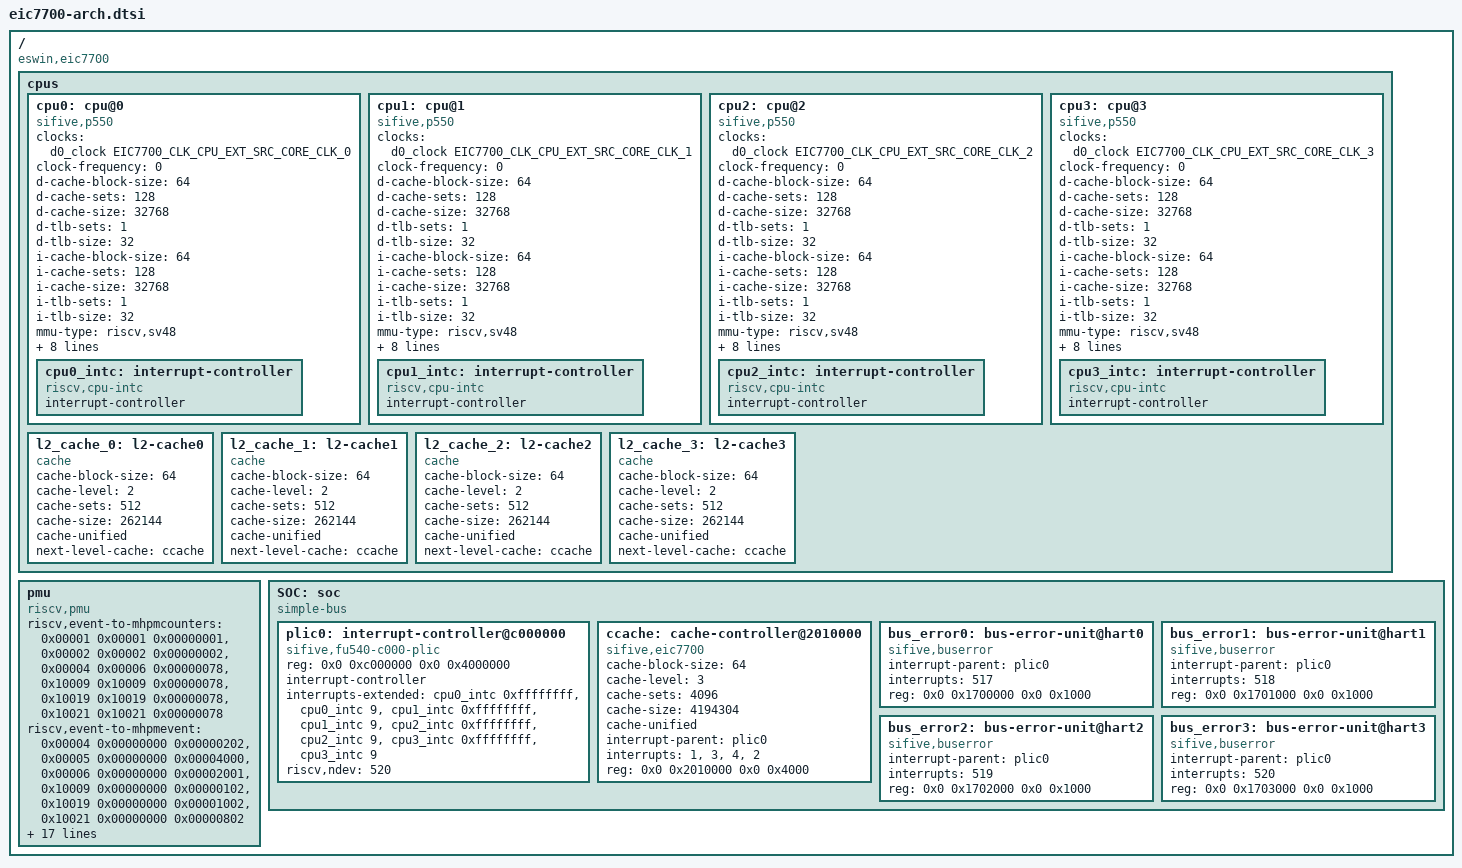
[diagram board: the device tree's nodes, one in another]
// SPDX-License-Identifier: (GPL-2.0 OR MIT)
/*
 * Copyright (c) 2024 Beijing ESWIN Computing Technology Co., Ltd.
 */

#include <dt-bindings/clock/eic7700-clock.h>

/ {
	#address-cells = <2>;
	#size-cells = <2>;
	compatible = "eswin,eic7700";

	cpus {
		#address-cells = <1>;
		#size-cells = <0>;
		cpu0: cpu@0 {
			compatible = "sifive,p550", "riscv";
			clocks = <&d0_clock EIC7700_CLK_CPU_EXT_SRC_CORE_CLK_0>;
			clock-frequency = <0>;
			device_type = "cpu";
			d-cache-block-size = <64>;
			d-cache-sets = <128>;
			d-cache-size = <32768>;
			d-tlb-sets = <1>;
			d-tlb-size = <32>;
			i-cache-block-size = <64>;
			i-cache-sets = <128>;
			i-cache-size = <32768>;
			i-tlb-sets = <1>;
			i-tlb-size = <32>;
			mmu-type = "riscv,sv48";
			next-level-cache = <&l2_cache_0>;
			operating-points-v2 = <&d0_cpu_opp_table>;
			reg = <0x0>;
			riscv,isa-base = "rv64i";
			riscv,isa-extensions = "i", "m", "a", "f", "d", "c", "h", "zicsr",
							"zifencei", "zba", "zbb", "sscofpmf";
			sifive,buserror = <&bus_error0>;
			tlb-split;
			cpu0_intc: interrupt-controller {
				#interrupt-cells = <1>;
				compatible = "riscv,cpu-intc";
				interrupt-controller;
			};
		};
		cpu1: cpu@1 {
			compatible = "sifive,p550", "riscv";
			clocks = <&d0_clock EIC7700_CLK_CPU_EXT_SRC_CORE_CLK_1>;
			clock-frequency = <0>;
			device_type = "cpu";
			d-cache-block-size = <64>;
			d-cache-sets = <128>;
			d-cache-size = <32768>;
			d-tlb-sets = <1>;
			d-tlb-size = <32>;
			i-cache-block-size = <64>;
			i-cache-sets = <128>;
			i-cache-size = <32768>;
			i-tlb-sets = <1>;
			i-tlb-size = <32>;
			mmu-type = "riscv,sv48";
			next-level-cache = <&l2_cache_1>;
			operating-points-v2 = <&d0_cpu_opp_table>;
			reg = <0x1>;
			riscv,isa-base = "rv64i";
			riscv,isa-extensions = "i", "m", "a", "f", "d", "c", "h", "zicsr",
							"zifencei", "zba", "zbb", "sscofpmf";
			sifive,buserror = <&bus_error1>;
			tlb-split;
			cpu1_intc: interrupt-controller {
				#interrupt-cells = <1>;
				compatible = "riscv,cpu-intc";
				interrupt-controller;
			};
		};
		cpu2: cpu@2 {
			compatible = "sifive,p550", "riscv";
			clocks = <&d0_clock EIC7700_CLK_CPU_EXT_SRC_CORE_CLK_2>;
			clock-frequency = <0>;
			device_type = "cpu";
			d-cache-block-size = <64>;
			d-cache-sets = <128>;
			d-cache-size = <32768>;
			d-tlb-sets = <1>;
			d-tlb-size = <32>;
			i-cache-block-size = <64>;
			i-cache-sets = <128>;
			i-cache-size = <32768>;
			i-tlb-sets = <1>;
			i-tlb-size = <32>;
			mmu-type = "riscv,sv48";
			next-level-cache = <&l2_cache_2>;
			operating-points-v2 = <&d0_cpu_opp_table>;
			reg = <0x2>;
			riscv,isa-base = "rv64i";
			riscv,isa-extensions = "i", "m", "a", "f", "d", "c", "h", "zicsr",
							"zifencei", "zba", "zbb", "sscofpmf";
			sifive,buserror = <&bus_error2>;
			tlb-split;
			cpu2_intc: interrupt-controller {
				#interrupt-cells = <1>;
				compatible = "riscv,cpu-intc";
				interrupt-controller;
			};
		};
		cpu3: cpu@3 {
			compatible = "sifive,p550", "riscv";
			clocks = <&d0_clock EIC7700_CLK_CPU_EXT_SRC_CORE_CLK_3>;
			clock-frequency = <0>;
			device_type = "cpu";
			d-cache-block-size = <64>;
			d-cache-sets = <128>;
			d-cache-size = <32768>;
			d-tlb-sets = <1>;
			d-tlb-size = <32>;
			i-cache-block-size = <64>;
			i-cache-sets = <128>;
			i-cache-size = <32768>;
			i-tlb-sets = <1>;
			i-tlb-size = <32>;
			mmu-type = "riscv,sv48";
			next-level-cache = <&l2_cache_3>;
			operating-points-v2 = <&d0_cpu_opp_table>;
			reg = <0x3>;
			riscv,isa-base = "rv64i";
			riscv,isa-extensions = "i", "m", "a", "f", "d", "c", "h", "zicsr",
							"zifencei", "zba", "zbb", "sscofpmf";
			sifive,buserror = <&bus_error3>;
			tlb-split;
			cpu3_intc: interrupt-controller {
				#interrupt-cells = <1>;
				compatible = "riscv,cpu-intc";
				interrupt-controller;
			};
		};
		l2_cache_0: l2-cache0 {
			compatible = "cache";
			cache-block-size = <64>;
			cache-level = <2>;
			cache-sets = <512>;
			cache-size = <262144>;
			cache-unified;
			next-level-cache = <&ccache>;
		};
		l2_cache_1: l2-cache1 {
			compatible = "cache";
			cache-block-size = <64>;
			cache-level = <2>;
			cache-sets = <512>;
			cache-size = <262144>;
			cache-unified;
			next-level-cache = <&ccache>;
		};
		l2_cache_2: l2-cache2 {
			compatible = "cache";
			cache-block-size = <64>;
			cache-level = <2>;
			cache-sets = <512>;
			cache-size = <262144>;
			cache-unified;
			next-level-cache = <&ccache>;
		};
		l2_cache_3: l2-cache3 {
			compatible = "cache";
			cache-block-size = <64>;
			cache-level = <2>;
			cache-sets = <512>;
			cache-size = <262144>;
			cache-unified;
			next-level-cache = <&ccache>;
		};
	};

	pmu {
		compatible = "riscv,pmu";
		riscv,event-to-mhpmcounters =
				<0x00001 0x00001 0x00000001>,
				<0x00002 0x00002 0x00000002>,
				<0x00004 0x00006 0x00000078>,
				<0x10009 0x10009 0x00000078>,
				<0x10019 0x10019 0x00000078>,
				<0x10021 0x10021 0x00000078>;
		riscv,event-to-mhpmevent =
				<0x00004 0x00000000 0x00000202>,
				<0x00005 0x00000000 0x00004000>,
				<0x00006 0x00000000 0x00002001>,
				<0x10009 0x00000000 0x00000102>,
				<0x10019 0x00000000 0x00001002>,
				<0x10021 0x00000000 0x00000802>;
		riscv,raw-event-to-mhpmcounters =
				<0x00000000 0x00000000 0xffffffff 0x000000ff 0x00000078>,
				<0x00000000 0x00000001 0xffffffff 0xfffe07ff 0x00000078>,
				<0x00000000 0x00000002 0xffffffff 0xfffe00ff 0x00000078>,
				<0x00000000 0x00000003 0xfffffffc 0x000000ff 0x00000078>,
				<0x00000000 0x00000004 0xffffffc0 0x000000ff 0x00000078>,
				<0x00000000 0x00000005 0xffffffff 0xfffffdff 0x00000078>,
				<0x00000000 0x00000006 0xfffffe00 0x110204ff 0x00000078>,
				<0x00000000 0x00000007 0xffffffff 0xf00000ff 0x00000078>,
				<0x00000000 0x00000008 0xfffffe04 0x000000ff 0x00000078>,
				<0x00000000 0x00000009 0xffffffff 0xffffc0ff 0x00000078>,
				<0x00000000 0x0000000a 0xffffffff 0xf00000ff 0x00000078>,
				<0x00000000 0x0000000b 0xffffffff 0xfffffcff 0x00000078>,
				<0x00000000 0x0000000c 0xfffffff0 0x000000ff 0x00000078>,
				<0x00000000 0x0000000d 0xffffffff 0x800000ff 0x00000078>,
				<0x00000000 0x0000000e 0xffffffff 0xf80000ff 0x00000078>,
				<0x00000000 0x0000000f 0xfffffffc 0x000000ff 0x00000078>;
	};

	SOC: soc {
		#address-cells = <2>;
		#size-cells = <2>;
		compatible = "simple-bus";
		ranges;
		plic0: interrupt-controller@c000000 {
			compatible = "sifive,fu540-c000-plic", "sifive,plic-1.0.0";
			reg = <0x0 0xc000000 0x0 0x4000000>;
			#address-cells = <0>;
			#interrupt-cells = <1>;
			interrupt-controller;
			interrupts-extended =
				<&cpu0_intc 0xffffffff>, <&cpu0_intc 9>,
				<&cpu1_intc 0xffffffff>, <&cpu1_intc 9>,
				<&cpu2_intc 0xffffffff>, <&cpu2_intc 9>,
				<&cpu3_intc 0xffffffff>, <&cpu3_intc 9>;
			riscv,ndev = <520>;
		};
		ccache: cache-controller@2010000 {
			compatible = "sifive,eic7700";
			cache-block-size = <64>;
			cache-level = <3>;
			cache-sets = <4096>;
			cache-size = <4194304>;
			cache-unified;
			interrupt-parent = <&plic0>;
			interrupts = <1>, <3>, <4>, <2>;
			reg = <0x0 0x2010000 0x0 0x4000>;
		};
		bus_error0: bus-error-unit@hart0 {
			compatible = "sifive,buserror";
			interrupt-parent = <&plic0>;
			interrupts = <517>;
			reg = <0x0 0x1700000 0x0 0x1000>;
		};
		bus_error1: bus-error-unit@hart1 {
			compatible = "sifive,buserror";
			interrupt-parent = <&plic0>;
			interrupts = <518>;
			reg = <0x0 0x1701000 0x0 0x1000>;
		};
		bus_error2: bus-error-unit@hart2 {
			compatible = "sifive,buserror";
			interrupt-parent = <&plic0>;
			interrupts = <519>;
			reg = <0x0 0x1702000 0x0 0x1000>;
		};
		bus_error3: bus-error-unit@hart3 {
			compatible = "sifive,buserror";
			interrupt-parent = <&plic0>;
			interrupts = <520>;
			reg = <0x0 0x1703000 0x0 0x1000>;
		};
	};
};
